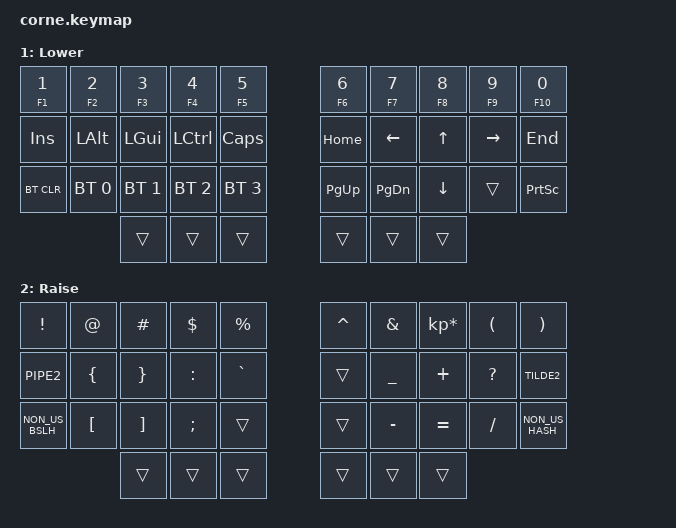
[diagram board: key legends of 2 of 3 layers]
/*
 * Copyright (c) 2020 The ZMK Contributors
 *
 * SPDX-License-Identifier: MIT
 */

#include <behaviors.dtsi>
#include <dt-bindings/zmk/keys.h>
#include <dt-bindings/zmk/bt.h>


#define HRML(k2,k3,k4) &hr LALT k2  &hr LGUI k3  &hr LCTRL k4
#define HRMR(k1,k2,k3) &hr LCTRL k1  &hr LGUI k2  &hr LALT k3

/ {
    chosen {
      zmk,matrix_transform = &five_column_transform;
    };

    behaviors {
        lt {
            flavor = "hold-preferred";
        };
        hr: hold_for_home_row {
            compatible = "zmk,behavior-hold-tap";
            #binding-cells = <2>;
            flavor = "balanced";
            tapping-term-ms = <200>;
            require-prior-idle-ms = <150>;
            bindings = <&kp>, <&kp>;
        };
        fn: hold_for_fn {
            compatible = "zmk,behavior-hold-tap";
            #binding-cells = <2>;
            flavor = "tap-preferred";
            tapping-term-ms = <200>;
            require-prior-idle-ms = <150>;
            bindings = <&kp>, <&kp>;
        };
    };
        keymap {
                compatible = "zmk,keymap";

                default_layer {
// -----------------------------------------------------------------------------------------
// |  Q  |  W  |  E  |  R  |  T  |     |  Y   |  U  |  I   | O |  P   |
// |  A  |  S  |  D  |  F  |  G  |     |  H   |  J  |  K   | L |  '   | 
// |  Z  |  X  |  C  |  V  |  B  |     |  N   |  M  |  ,   | . | BSPC |
//             | ESC | TAB | SPC |     | SHFT | ENT | DEL  |
                        display-name = "Base";
                        bindings = <
   &kp Q &kp W   &kp E &kp R &kp T     &kp Y      &kp U     &kp I     &kp O   &kp P
   &kp A HRML(S, D,    F)    &kp G     &kp H      HRMR(J,   K,        L)      &kp SQT
   &kp Z &kp X   &kp C &kp V &kp B     &kp N      &kp M     &kp COMMA &kp DOT &kp BSPC
       &kp ESC &lt 1 TAB &kp SPACE     &kp LSHIFT &lt 2 RET &kp DEL
                        >;
                };

                lower_layer {
// -----------------------------------------------------------------------------------------
// | 1     |  2  |  3  |  4   |  5   |     |  6   |  7    |  8   |  9  |  0    |
// |  INS  | ALT | GUI | CTRL | CAPS |     | HOME | LFT   |  UP  | RGT | END   |
// | BTCLR | BT1 | BT2 | BT3  | BT4  |     | PGUP | PGDWN |  DWN |  .  | PSCRN |
//               |     |      |      |     |      |     |     |
                        display-name = "Lower";
                        bindings = <
   &fn F1 N1  &fn F2 N2    &fn F3 N3    &fn F4 N4    &fn F5 N5        &fn F6 N6 &fn F7 N7   &fn F8 N8 &fn F9 N9 &fn F10 N0
   &kp INS    &kp LALT     &kp LGUI     &kp LCTRL    &kp CAPS         &kp HOME  &kp LEFT    &kp UP    &kp RIGHT &kp END 
   &bt BT_CLR &bt BT_SEL 0 &bt BT_SEL 1 &bt BT_SEL 2 &bt BT_SEL 3     &kp PG_UP &kp PG_DN   &kp DOWN  &trans    &kp PRINTSCREEN 
                           &trans       &trans       &trans           &trans    &trans      &trans
                        >;
                };

                raise_layer {
// -----------------------------------------------------------------------------------------
// | ! | " | £ | $ | % |     | ^ | & | * | ( | ) |
// | | | { | } | : | ` |     |   | _ | + | ? | ~ |
// | \ | [ | ] | ; |   |     |   | - | = | / | # |
//         |   |   |   |     |   |   |   |
                        display-name = "Raise";
                        bindings = <

   &kp EXCL        &kp AT   &kp HASH &kp DLLR  &kp PRCNT        &kp CARET &kp AMPS  &kp KP_MULTIPLY &kp LPAR  &kp RPAR
   &kp PIPE2       &kp LBRC &kp RBRC &kp COLON &kp GRAVE        &trans    &kp UNDER &kp PLUS        &kp QMARK &kp TILDE2
   &kp NON_US_BSLH &kp LBKT &kp RBKT &kp SEMI  &trans           &trans    &kp MINUS &kp EQUAL       &kp FSLH  &kp NON_US_HASH
                            &trans   &trans    &trans           &trans    &trans    &trans
                        >;
                };
        };
};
